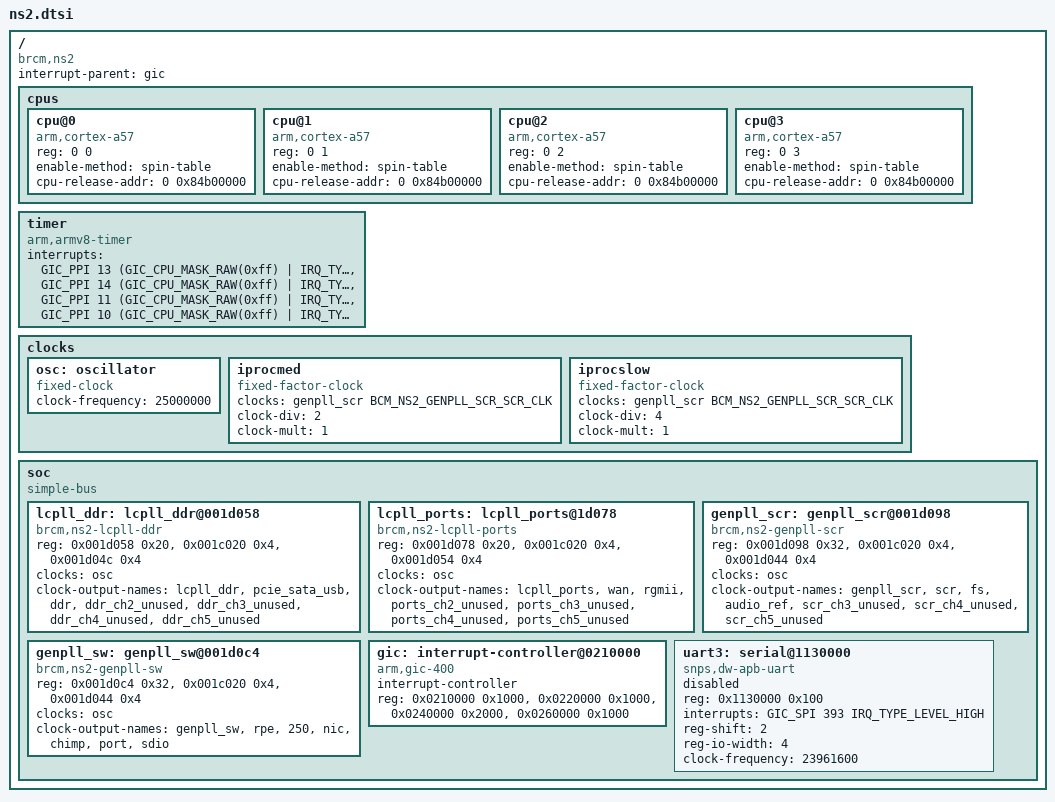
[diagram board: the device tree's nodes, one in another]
/*
 *  BSD LICENSE
 *
 *  Copyright(c) 2015 Broadcom Corporation.  All rights reserved.
 *
 *  Redistribution and use in source and binary forms, with or without
 *  modification, are permitted provided that the following conditions
 *  are met:
 *
 *    * Redistributions of source code must retain the above copyright
 *      notice, this list of conditions and the following disclaimer.
 *    * Redistributions in binary form must reproduce the above copyright
 *      notice, this list of conditions and the following disclaimer in
 *      the documentation and/or other materials provided with the
 *      distribution.
 *    * Neither the name of Broadcom Corporation nor the names of its
 *      contributors may be used to endorse or promote products derived
 *      from this software without specific prior written permission.
 *
 *  THIS SOFTWARE IS PROVIDED BY THE COPYRIGHT HOLDERS AND CONTRIBUTORS
 *  "AS IS" AND ANY EXPRESS OR IMPLIED WARRANTIES, INCLUDING, BUT NOT
 *  LIMITED TO, THE IMPLIED WARRANTIES OF MERCHANTABILITY AND FITNESS FOR
 *  A PARTICULAR PURPOSE ARE DISCLAIMED. IN NO EVENT SHALL THE COPYRIGHT
 *  OWNER OR CONTRIBUTORS BE LIABLE FOR ANY DIRECT, INDIRECT, INCIDENTAL,
 *  SPECIAL, EXEMPLARY, OR CONSEQUENTIAL DAMAGES (INCLUDING, BUT NOT
 *  LIMITED TO, PROCUREMENT OF SUBSTITUTE GOODS OR SERVICES; LOSS OF USE,
 *  DATA, OR PROFITS; OR BUSINESS INTERRUPTION) HOWEVER CAUSED AND ON ANY
 *  THEORY OF LIABILITY, WHETHER IN CONTRACT, STRICT LIABILITY, OR TORT
 *  (INCLUDING NEGLIGENCE OR OTHERWISE) ARISING IN ANY WAY OUT OF THE USE
 * OF THIS SOFTWARE, EVEN IF ADVISED OF THE POSSIBILITY OF SUCH DAMAGE.
 */

#include <dt-bindings/interrupt-controller/arm-gic.h>
#include <dt-bindings/clock/bcm-ns2.h>

/memreserve/ 0x84b00000 0x00000008;

/ {
	compatible = "brcm,ns2";
	interrupt-parent = <&gic>;
	#address-cells = <2>;
	#size-cells = <2>;

	cpus {
		#address-cells = <2>;
		#size-cells = <0>;

		cpu@0 {
			device_type = "cpu";
			compatible = "arm,cortex-a57", "arm,armv8";
			reg = <0 0>;
			enable-method = "spin-table";
			cpu-release-addr = <0 0x84b00000>;
		};

		cpu@1 {
			device_type = "cpu";
			compatible = "arm,cortex-a57", "arm,armv8";
			reg = <0 1>;
			enable-method = "spin-table";
			cpu-release-addr = <0 0x84b00000>;
		};

		cpu@2 {
			device_type = "cpu";
			compatible = "arm,cortex-a57", "arm,armv8";
			reg = <0 2>;
			enable-method = "spin-table";
			cpu-release-addr = <0 0x84b00000>;
		};

		cpu@3 {
			device_type = "cpu";
			compatible = "arm,cortex-a57", "arm,armv8";
			reg = <0 3>;
			enable-method = "spin-table";
			cpu-release-addr = <0 0x84b00000>;
		};
	};

	timer {
		compatible = "arm,armv8-timer";
		interrupts = <GIC_PPI 13 (GIC_CPU_MASK_RAW(0xff) |
			      IRQ_TYPE_EDGE_RISING)>,
			     <GIC_PPI 14 (GIC_CPU_MASK_RAW(0xff) |
			      IRQ_TYPE_EDGE_RISING)>,
			     <GIC_PPI 11 (GIC_CPU_MASK_RAW(0xff) |
			      IRQ_TYPE_EDGE_RISING)>,
			     <GIC_PPI 10 (GIC_CPU_MASK_RAW(0xff) |
			      IRQ_TYPE_EDGE_RISING)>;
	};

	clocks {
		#address-cells = <1>;
		#size-cells = <1>;

		osc: oscillator {
			#clock-cells = <0>;
			compatible = "fixed-clock";
			clock-frequency = <25000000>;
		};

		iprocmed: iprocmed {
			#clock-cells = <0>;
			compatible = "fixed-factor-clock";
			clocks = <&genpll_scr BCM_NS2_GENPLL_SCR_SCR_CLK>;
			clock-div = <2>;
			clock-mult = <1>;
		};

		iprocslow: iprocslow {
			#clock-cells = <0>;
			compatible = "fixed-factor-clock";
			clocks = <&genpll_scr BCM_NS2_GENPLL_SCR_SCR_CLK>;
			clock-div = <4>;
			clock-mult = <1>;
		};
	};

	soc: soc {
		compatible = "simple-bus";
		#address-cells = <1>;
		#size-cells = <1>;
		ranges = <0 0 0 0xffffffff>;
		ranges = <0 0 0x65000000 0x01130100>;

		lcpll_ddr: lcpll_ddr@001d058 {
			#clock-cells = <1>;
			compatible = "brcm,ns2-lcpll-ddr";
			reg = <0x001d058 0x20>,
			      <0x001c020 0x4>,
			      <0x001d04c 0x4>;
			clocks = <&osc>;
			clock-output-names = "lcpll_ddr", "pcie_sata_usb",
					     "ddr", "ddr_ch2_unused",
					     "ddr_ch3_unused", "ddr_ch4_unused",
					     "ddr_ch5_unused";
		};

		lcpll_ports: lcpll_ports@1d078 {
			#clock-cells = <1>;
			compatible = "brcm,ns2-lcpll-ports";
			reg = <0x001d078 0x20>,
			      <0x001c020 0x4>,
			      <0x001d054 0x4>;
			clocks = <&osc>;
			clock-output-names = "lcpll_ports", "wan", "rgmii",
					     "ports_ch2_unused",
					     "ports_ch3_unused",
					     "ports_ch4_unused",
					     "ports_ch5_unused";
		};

		genpll_scr: genpll_scr@001d098 {
			#clock-cells = <1>;
			compatible = "brcm,ns2-genpll-scr";
			reg = <0x001d098 0x32>,
			      <0x001c020 0x4>,
			      <0x001d044 0x4>;
			clocks = <&osc>;
			clock-output-names = "genpll_scr", "scr", "fs",
					     "audio_ref", "scr_ch3_unused",
					     "scr_ch4_unused", "scr_ch5_unused";
		};

		genpll_sw: genpll_sw@001d0c4 {
			#clock-cells = <1>;
			compatible = "brcm,ns2-genpll-sw";
			reg = <0x001d0c4 0x32>,
			      <0x001c020 0x4>,
			      <0x001d044 0x4>;
			clocks = <&osc>;
			clock-output-names = "genpll_sw", "rpe", "250", "nic",
					     "chimp", "port", "sdio";
		};

		gic: interrupt-controller@0210000 {
			compatible = "arm,gic-400";
			#interrupt-cells = <3>;
			interrupt-controller;
			reg = <0x0210000 0x1000>,
			      <0x0220000 0x1000>,
			      <0x0240000 0x2000>,
			      <0x0260000 0x1000>;
		};

		uart3: serial@1130000 {
			compatible = "snps,dw-apb-uart";
			reg = <0x1130000 0x100>;
			interrupts = <GIC_SPI 393 IRQ_TYPE_LEVEL_HIGH>;
			reg-shift = <2>;
			reg-io-width = <4>;
			clock-frequency = <23961600>;
			status = "disabled";
		};
	};
};
